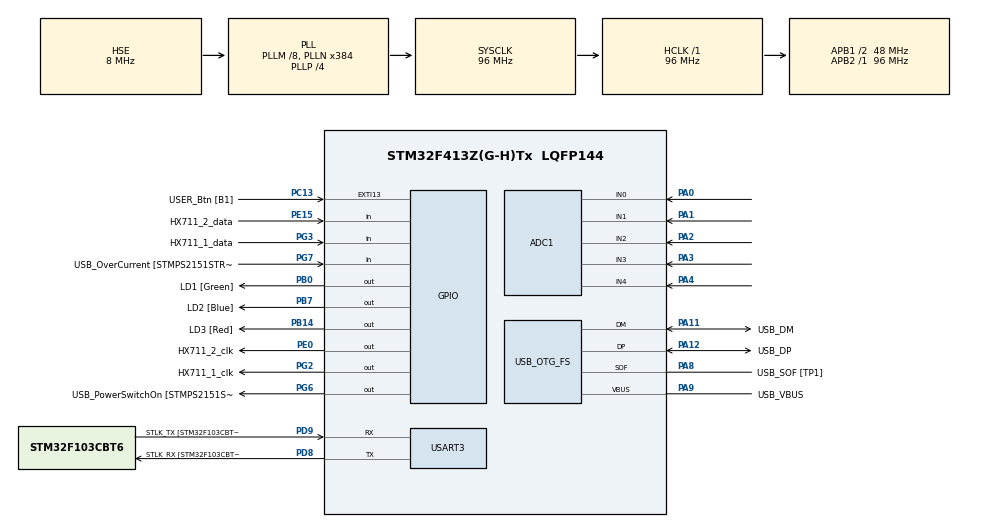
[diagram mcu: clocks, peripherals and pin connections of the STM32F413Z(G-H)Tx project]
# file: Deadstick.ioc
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ADC1.Channel-0\#ChannelRegularConversion=ADC_CHANNEL_0
ADC1.Channel-1\#ChannelRegularConversion=ADC_CHANNEL_1
ADC1.Channel-2\#ChannelRegularConversion=ADC_CHANNEL_2
ADC1.Channel-3\#ChannelRegularConversion=ADC_CHANNEL_3
ADC1.Channel-4\#ChannelRegularConversion=ADC_CHANNEL_4
ADC1.EOCSelection=ADC_EOC_SEQ_CONV
ADC1.NbrOfConversion=5
ADC1.NbrOfConversionFlag=1
ADC1.Rank-0\#ChannelRegularConversion=1
ADC1.Rank-1\#ChannelRegularConversion=2
ADC1.Rank-2\#ChannelRegularConversion=3
ADC1.Rank-3\#ChannelRegularConversion=4
ADC1.Rank-4\#ChannelRegularConversion=5
ADC1.SamplingTime-0\#ChannelRegularConversion=ADC_SAMPLETIME_15CYCLES
ADC1.SamplingTime-1\#ChannelRegularConversion=ADC_SAMPLETIME_15CYCLES
ADC1.SamplingTime-2\#ChannelRegularConversion=ADC_SAMPLETIME_15CYCLES
ADC1.SamplingTime-3\#ChannelRegularConversion=ADC_SAMPLETIME_15CYCLES
ADC1.SamplingTime-4\#ChannelRegularConversion=ADC_SAMPLETIME_15CYCLES
ADC1.ScanConvMode=ENABLE
ADC1.master=1
Dma.ADC1.0.Direction=DMA_PERIPH_TO_MEMORY
Dma.ADC1.0.FIFOMode=DMA_FIFOMODE_DISABLE
Dma.ADC1.0.Instance=DMA2_Stream0
Dma.ADC1.0.MemDataAlignment=DMA_MDATAALIGN_HALFWORD
Dma.ADC1.0.MemInc=DMA_MINC_ENABLE
Dma.ADC1.0.Mode=DMA_CIRCULAR
Dma.ADC1.0.PeriphDataAlignment=DMA_PDATAALIGN_HALFWORD
Dma.ADC1.0.PeriphInc=DMA_PINC_DISABLE
Dma.ADC1.0.Priority=DMA_PRIORITY_LOW
Dma.Request0=ADC1
Mcu.Family=STM32F4
Mcu.Name=STM32F413Z(G-H)Tx
Mcu.Package=LQFP144
Mcu.UserConstants=CUSTOM_HID_EPIN_SIZE,64;CUSTOM_HID_EPOUT_SIZE,64
NVIC.DMA2_Stream0_IRQn=true\:0\:0\:false\:false\:true\:false\:true\:true
NVIC.OTG_FS_IRQn=true\:0\:0\:false\:false\:true\:false\:true\:true
NVIC.PriorityGroup=NVIC_PRIORITYGROUP_4
PA0.Signal=ADCx_IN0
PA1.Signal=ADCx_IN1
PA10.GPIO_Label=USB_ID
PA10.Signal=USB_OTG_FS_ID
PA11.GPIO_Label=USB_DM
PA11.Mode=Device_Only
PA11.Signal=USB_OTG_FS_DM
PA12.GPIO_Label=USB_DP
PA12.Mode=Device_Only
PA12.Signal=USB_OTG_FS_DP
PA13.GPIO_Label=TMS
PA13.Mode=Serial_Wire
PA13.Signal=SYS_JTMS-SWDIO
PA14.GPIO_Label=TCK
PA14.Mode=Serial_Wire
PA14.Signal=SYS_JTCK-SWCLK
PA2.Signal=ADCx_IN2
PA3.Signal=ADCx_IN3
PA4.Signal=ADCx_IN4
PA8.GPIO_Label=USB_SOF [TP1]
PA8.Mode=Activate_SOF_FS
PA8.Signal=USB_OTG_FS_SOF
PA9.GPIO_Label=USB_VBUS
PA9.Mode=Activate_VBUS
PA9.Signal=USB_OTG_FS_VBUS
PB0.GPIO_Label=LD1 [Green]
PB0.Signal=GPIO_Output
PB14.GPIO_Label=LD3 [Red]
PB14.Signal=GPIO_Output
PB3.GPIO_Label=SWO
PB3.Signal=SYS_JTDO-SWO
PB7.GPIO_Label=LD2 [Blue]
PB7.Signal=GPIO_Output
PC13.GPIO_Label=USER_Btn [B1]
PC13.Signal=GPXTI13
PC14-OSC32_IN.Signal=RCC_OSC32_IN
PC15-OSC32_OUT.Signal=RCC_OSC32_OUT
PD8.GPIO_Label=STLK_RX [STM32F103CBT6_PA3]
PD8.Mode=Asynchronous
PD8.Signal=USART3_TX
PD9.GPIO_Label=STLK_TX [STM32F103CBT6_PA2]
PD9.Mode=Asynchronous
PD9.Signal=USART3_RX
PE0.GPIO_Label=HX711_2_clk
PE0.Signal=GPIO_Output
PE15.GPIO_Label=HX711_2_data
PE15.GPIO_PuPd=GPIO_PULLUP
PE15.Signal=GPIO_Input
PG2.GPIO_Label=HX711_1_clk
PG2.Signal=GPIO_Output
PG3.GPIO_Label=HX711_1_data
PG3.GPIO_PuPd=GPIO_PULLUP
PG3.Signal=GPIO_Input
PG6.GPIO_Label=USB_PowerSwitchOn [STMPS2151STR_EN]
PG6.Signal=GPIO_Output
PG7.GPIO_Label=USB_OverCurrent [STMPS2151STR_FAULT]
PG7.Signal=GPIO_Input
PH0\ -\ OSC_IN.GPIO_Label=MCO
PH0\ -\ OSC_IN.Mode=HSE-External-Clock-Source
PH0\ -\ OSC_IN.Signal=RCC_OSC_IN
PH1\ -\ OSC_OUT.Mode=HSE-External-Clock-Source
PH1\ -\ OSC_OUT.Signal=RCC_OSC_OUT
ProjectManager.HeapSize=0x200
ProjectManager.StackSize=0x400
ProjectManager.TargetToolchain=STM32CubeIDE
RCC.48MHZClocksFreq_Value=24000000
RCC.AHBFreq_Value=96000000
RCC.APB1CLKDivider=RCC_HCLK_DIV2
RCC.APB1Freq_Value=48000000
RCC.APB1TimFreq_Value=96000000
RCC.APB2Freq_Value=96000000
RCC.APB2TimFreq_Value=96000000
RCC.CortexFreq_Value=96000000
RCC.HCLKFreq_Value=96000000
RCC.HSE_VALUE=8000000
RCC.HSI_VALUE=16000000
RCC.PLLM=8
RCC.PLLMUL=RCC_PLL_MUL9
RCC.PLLN=384
RCC.PLLP=RCC_PLLP_DIV4
RCC.PLLQ=8
RCC.PRESCALERUSB=RCC_USBCLKSOURCE_PLL_DIV1_5
RCC.SYSCLKFreq_VALUE=96000000
RCC.SYSCLKSource=RCC_SYSCLKSOURCE_PLLCLK
RCC.SYSCLKSourceVirtual=RCC_SYSCLKSOURCE_PLLCLK
RCC.USBFreq_Value=48000000
RCC.VCOOutputFreq_Value=384000000
SH.ADCx_IN0.0=ADC1_IN0,IN0
SH.ADCx_IN1.0=ADC1_IN1,IN1
SH.ADCx_IN2.0=ADC1_IN2,IN2
SH.ADCx_IN3.0=ADC1_IN3,IN3
SH.ADCx_IN4.0=ADC1_IN4,IN4
TIM5.Prescaler=95
USART3.VirtualMode=VM_ASYNC
USB_DEVICE.CLASS_NAME_FS=CUSTOM_HID
USB_DEVICE.CONFIGURATION_STRING_CUSTOMHID_FS=Forse Sensing Joystick
USB_DEVICE.CUSTOM_HID_FS_BINTERVAL=0x05
USB_DEVICE.PID_CUSTOMHID_FS=0x5713
USB_DEVICE.PRODUCT_STRING_CUSTOMHID_FS=Deadstick
USB_DEVICE.USBD_CUSTOMHID_OUTREPORT_BUF_SIZE=64
USB_DEVICE.USBD_CUSTOM_HID_REPORT_DESC_SIZE=96
USB_DEVICE.VID=0x0483
USB_DEVICE.VirtualMode=CustomHid
USB_DEVICE.VirtualModeFS=Custom_Hid_FS
USB_OTG_FS.VirtualMode=Device_Only
USB_OTG_FS.battery_charging_enable=DISABLE
VP_TIM5_VS_ClockSourceINT.Mode=Internal
VP_USB_DEVICE_VS_USB_DEVICE_CUSTOM_HID_FS.Mode=CUSTOM_HID_FS
board=NUCLEO-F413ZH

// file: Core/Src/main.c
/* USER CODE BEGIN Header */
/**
  ******************************************************************************
  * @file           : main.c
  * @brief          : Main program body
  ******************************************************************************
  * @attention
  *
  * Copyright (c) 2022 STMicroelectronics.
  * All rights reserved.
  *
  * This software is licensed under terms that can be found in the LICENSE file
  * in the root directory of this software component.
  * If no LICENSE file comes with this software, it is provided AS-IS.
  *
  ******************************************************************************
  */
/* USER CODE END Header */
#include "main.h"
#include "usb_device.h"

/* USER CODE BEGIN Includes */
#include "main_loop_api.h"
#include "stdio_redirection.h"
/* USER CODE END Includes */

ADC_HandleTypeDef hadc1;
DMA_HandleTypeDef hdma_adc1;

TIM_HandleTypeDef htim5;

UART_HandleTypeDef huart3;

void SystemClock_Config(void);
static void MX_GPIO_Init(void);
static void MX_DMA_Init(void);
static void MX_USART3_UART_Init(void);
static void MX_ADC1_Init(void);
static void MX_TIM5_Init(void);

int main(void)
{
  /* USER CODE BEGIN 1 */
    pTimerHtim = &htim5;    /*htim5 used by Timer class*/
    pHadc = &hadc1;         /*pointer to hadc1, which will be used in another module*/
  /* USER CODE END 1 */

  /* MCU Configuration--------------------------------------------------------*/

  /* Reset of all peripherals, Initializes the Flash interface and the Systick. */
  HAL_Init();

  /* Configure the system clock */
  SystemClock_Config();

  /* Initialize all configured peripherals */
  MX_GPIO_Init();
  MX_DMA_Init();
  MX_USART3_UART_Init();
  MX_USB_DEVICE_Init();
  MX_ADC1_Init();
  MX_TIM5_Init();
  /* USER CODE BEGIN 2 */
  redirectStdio(&huart3);     /*redirect stdio to console UART*/
  /* request the first pass of ADC conversions */
  HAL_ADC_Start_DMA(&hadc1, (uint32_t*)adcConvBuffer, hadc1.Init.NbrOfConversion);
  /* USER CODE END 2 */

  /* Infinite loop */
  /* USER CODE BEGIN WHILE */
  mainLoop();   /*it never returns from this function*/

  while (1)
  {
    /* USER CODE END WHILE */

  }
}

void SystemClock_Config(void)
{
  RCC_OscInitTypeDef RCC_OscInitStruct = {0};
  RCC_ClkInitTypeDef RCC_ClkInitStruct = {0};

  /** Configure the main internal regulator output voltage
  */
  __HAL_RCC_PWR_CLK_ENABLE();
  __HAL_PWR_VOLTAGESCALING_CONFIG(PWR_REGULATOR_VOLTAGE_SCALE1);

  /** Initializes the RCC Oscillators according to the specified parameters
  * in the RCC_OscInitTypeDef structure.
  */
  RCC_OscInitStruct.OscillatorType = RCC_OSCILLATORTYPE_HSE;
  RCC_OscInitStruct.HSEState = RCC_HSE_BYPASS;
  RCC_OscInitStruct.PLL.PLLState = RCC_PLL_ON;
  RCC_OscInitStruct.PLL.PLLSource = RCC_PLLSOURCE_HSE;
  RCC_OscInitStruct.PLL.PLLM = 8;
  RCC_OscInitStruct.PLL.PLLN = 384;
  RCC_OscInitStruct.PLL.PLLP = RCC_PLLP_DIV4;
  RCC_OscInitStruct.PLL.PLLQ = 8;
  RCC_OscInitStruct.PLL.PLLR = 2;
  if (HAL_RCC_OscConfig(&RCC_OscInitStruct) != HAL_OK)
  {
    Error_Handler();
  }

  /** Initializes the CPU, AHB and APB buses clocks
  */
  RCC_ClkInitStruct.ClockType = RCC_CLOCKTYPE_HCLK|RCC_CLOCKTYPE_SYSCLK
                              |RCC_CLOCKTYPE_PCLK1|RCC_CLOCKTYPE_PCLK2;
  RCC_ClkInitStruct.SYSCLKSource = RCC_SYSCLKSOURCE_PLLCLK;
  RCC_ClkInitStruct.AHBCLKDivider = RCC_SYSCLK_DIV1;
  RCC_ClkInitStruct.APB1CLKDivider = RCC_HCLK_DIV2;
  RCC_ClkInitStruct.APB2CLKDivider = RCC_HCLK_DIV1;

  if (HAL_RCC_ClockConfig(&RCC_ClkInitStruct, FLASH_LATENCY_3) != HAL_OK)
  {
    Error_Handler();
  }
}

static void MX_ADC1_Init(void)
{

  ADC_ChannelConfTypeDef sConfig = {0};

  /** Configure the global features of the ADC (Clock, Resolution, Data Alignment and number of conversion)
  */
  hadc1.Instance = ADC1;
  hadc1.Init.ClockPrescaler = ADC_CLOCK_SYNC_PCLK_DIV4;
  hadc1.Init.Resolution = ADC_RESOLUTION_12B;
  hadc1.Init.ScanConvMode = ENABLE;
  hadc1.Init.ContinuousConvMode = DISABLE;
  hadc1.Init.DiscontinuousConvMode = DISABLE;
  hadc1.Init.ExternalTrigConvEdge = ADC_EXTERNALTRIGCONVEDGE_NONE;
  hadc1.Init.ExternalTrigConv = ADC_SOFTWARE_START;
  hadc1.Init.DataAlign = ADC_DATAALIGN_RIGHT;
  hadc1.Init.NbrOfConversion = 5;
  hadc1.Init.DMAContinuousRequests = DISABLE;
  hadc1.Init.EOCSelection = ADC_EOC_SEQ_CONV;
  if (HAL_ADC_Init(&hadc1) != HAL_OK)
  {
    Error_Handler();
  }

  /** Configure for the selected ADC regular channel its corresponding rank in the sequencer and its sample time.
  */
  sConfig.Channel = ADC_CHANNEL_0;
  sConfig.Rank = 1;
  sConfig.SamplingTime = ADC_SAMPLETIME_15CYCLES;
  if (HAL_ADC_ConfigChannel(&hadc1, &sConfig) != HAL_OK)
  {
    Error_Handler();
  }

  /** Configure for the selected ADC regular channel its corresponding rank in the sequencer and its sample time.
  */
  sConfig.Channel = ADC_CHANNEL_1;
  sConfig.Rank = 2;
  if (HAL_ADC_ConfigChannel(&hadc1, &sConfig) != HAL_OK)
  {
    Error_Handler();
  }

  /** Configure for the selected ADC regular channel its corresponding rank in the sequencer and its sample time.
  */
  sConfig.Channel = ADC_CHANNEL_2;
  sConfig.Rank = 3;
  if (HAL_ADC_ConfigChannel(&hadc1, &sConfig) != HAL_OK)
  {
    Error_Handler();
  }

  /** Configure for the selected ADC regular channel its corresponding rank in the sequencer and its sample time.
  */
  sConfig.Channel = ADC_CHANNEL_3;
  sConfig.Rank = 4;
  if (HAL_ADC_ConfigChannel(&hadc1, &sConfig) != HAL_OK)
  {
    Error_Handler();
  }

  /** Configure for the selected ADC regular channel its corresponding rank in the sequencer and its sample time.
  */
  sConfig.Channel = ADC_CHANNEL_4;
  sConfig.Rank = 5;
  if (HAL_ADC_ConfigChannel(&hadc1, &sConfig) != HAL_OK)
  {
    Error_Handler();
  }

}

static void MX_TIM5_Init(void)
{

  TIM_ClockConfigTypeDef sClockSourceConfig = {0};
  TIM_MasterConfigTypeDef sMasterConfig = {0};

  htim5.Instance = TIM5;
  htim5.Init.Prescaler = 95;
  htim5.Init.CounterMode = TIM_COUNTERMODE_UP;
  htim5.Init.Period = 4294967295;
  htim5.Init.ClockDivision = TIM_CLOCKDIVISION_DIV1;
  htim5.Init.AutoReloadPreload = TIM_AUTORELOAD_PRELOAD_DISABLE;
  if (HAL_TIM_Base_Init(&htim5) != HAL_OK)
  {
    Error_Handler();
  }
  sClockSourceConfig.ClockSource = TIM_CLOCKSOURCE_INTERNAL;
  if (HAL_TIM_ConfigClockSource(&htim5, &sClockSourceConfig) != HAL_OK)
  {
    Error_Handler();
  }
  sMasterConfig.MasterOutputTrigger = TIM_TRGO_RESET;
  sMasterConfig.MasterSlaveMode = TIM_MASTERSLAVEMODE_DISABLE;
  if (HAL_TIMEx_MasterConfigSynchronization(&htim5, &sMasterConfig) != HAL_OK)
  {
    Error_Handler();
  }

}

static void MX_USART3_UART_Init(void)
{

  huart3.Instance = USART3;
  huart3.Init.BaudRate = 115200;
  huart3.Init.WordLength = UART_WORDLENGTH_8B;
  huart3.Init.StopBits = UART_STOPBITS_1;
  huart3.Init.Parity = UART_PARITY_NONE;
  huart3.Init.Mode = UART_MODE_TX_RX;
  huart3.Init.HwFlowCtl = UART_HWCONTROL_NONE;
  huart3.Init.OverSampling = UART_OVERSAMPLING_16;
  if (HAL_UART_Init(&huart3) != HAL_OK)
  {
    Error_Handler();
  }

}

static void MX_DMA_Init(void)
{

  /* DMA controller clock enable */
  __HAL_RCC_DMA2_CLK_ENABLE();

  /* DMA interrupt init */
  /* DMA2_Stream0_IRQn interrupt configuration */
  HAL_NVIC_SetPriority(DMA2_Stream0_IRQn, 0, 0);
  HAL_NVIC_EnableIRQ(DMA2_Stream0_IRQn);

}

static void MX_GPIO_Init(void)
{
  GPIO_InitTypeDef GPIO_InitStruct = {0};

  /* GPIO Ports Clock Enable */
  __HAL_RCC_GPIOC_CLK_ENABLE();
  __HAL_RCC_GPIOH_CLK_ENABLE();
  __HAL_RCC_GPIOA_CLK_ENABLE();
  __HAL_RCC_GPIOB_CLK_ENABLE();
  __HAL_RCC_GPIOE_CLK_ENABLE();
  __HAL_RCC_GPIOD_CLK_ENABLE();
  __HAL_RCC_GPIOG_CLK_ENABLE();

  /*Configure GPIO pin Output Level */
  HAL_GPIO_WritePin(GPIOB, LD1_Pin|LD3_Pin|LD2_Pin, GPIO_PIN_RESET);

  /*Configure GPIO pin Output Level */
  HAL_GPIO_WritePin(GPIOG, HX711_1_clk_Pin|USB_PowerSwitchOn_Pin, GPIO_PIN_RESET);

  /*Configure GPIO pin Output Level */
  HAL_GPIO_WritePin(HX711_2_clk_GPIO_Port, HX711_2_clk_Pin, GPIO_PIN_RESET);

  /*Configure GPIO pin : USER_Btn_Pin */
  GPIO_InitStruct.Pin = USER_Btn_Pin;
  GPIO_InitStruct.Mode = GPIO_MODE_IT_RISING;
  GPIO_InitStruct.Pull = GPIO_NOPULL;
  HAL_GPIO_Init(USER_Btn_GPIO_Port, &GPIO_InitStruct);

  /*Configure GPIO pins : LD1_Pin LD3_Pin LD2_Pin */
  GPIO_InitStruct.Pin = LD1_Pin|LD3_Pin|LD2_Pin;
  GPIO_InitStruct.Mode = GPIO_MODE_OUTPUT_PP;
  GPIO_InitStruct.Pull = GPIO_NOPULL;
  GPIO_InitStruct.Speed = GPIO_SPEED_FREQ_LOW;
  HAL_GPIO_Init(GPIOB, &GPIO_InitStruct);

  /*Configure GPIO pin : HX711_2_data_Pin */
  GPIO_InitStruct.Pin = HX711_2_data_Pin;
  GPIO_InitStruct.Mode = GPIO_MODE_INPUT;
  GPIO_InitStruct.Pull = GPIO_PULLUP;
  HAL_GPIO_Init(HX711_2_data_GPIO_Port, &GPIO_InitStruct);

  /*Configure GPIO pins : HX711_1_clk_Pin USB_PowerSwitchOn_Pin */
  GPIO_InitStruct.Pin = HX711_1_clk_Pin|USB_PowerSwitchOn_Pin;
  GPIO_InitStruct.Mode = GPIO_MODE_OUTPUT_PP;
  GPIO_InitStruct.Pull = GPIO_NOPULL;
  GPIO_InitStruct.Speed = GPIO_SPEED_FREQ_LOW;
  HAL_GPIO_Init(GPIOG, &GPIO_InitStruct);

  /*Configure GPIO pin : HX711_1_data_Pin */
  GPIO_InitStruct.Pin = HX711_1_data_Pin;
  GPIO_InitStruct.Mode = GPIO_MODE_INPUT;
  GPIO_InitStruct.Pull = GPIO_PULLUP;
  HAL_GPIO_Init(HX711_1_data_GPIO_Port, &GPIO_InitStruct);

  /*Configure GPIO pin : USB_OverCurrent_Pin */
  GPIO_InitStruct.Pin = USB_OverCurrent_Pin;
  GPIO_InitStruct.Mode = GPIO_MODE_INPUT;
  GPIO_InitStruct.Pull = GPIO_NOPULL;
  HAL_GPIO_Init(USB_OverCurrent_GPIO_Port, &GPIO_InitStruct);

  /*Configure GPIO pin : HX711_2_clk_Pin */
  GPIO_InitStruct.Pin = HX711_2_clk_Pin;
  GPIO_InitStruct.Mode = GPIO_MODE_OUTPUT_PP;
  GPIO_InitStruct.Pull = GPIO_NOPULL;
  GPIO_InitStruct.Speed = GPIO_SPEED_FREQ_LOW;
  HAL_GPIO_Init(HX711_2_clk_GPIO_Port, &GPIO_InitStruct);

}

void Error_Handler(void)
{
  __disable_irq();
  while (1)
  {
  }
}
